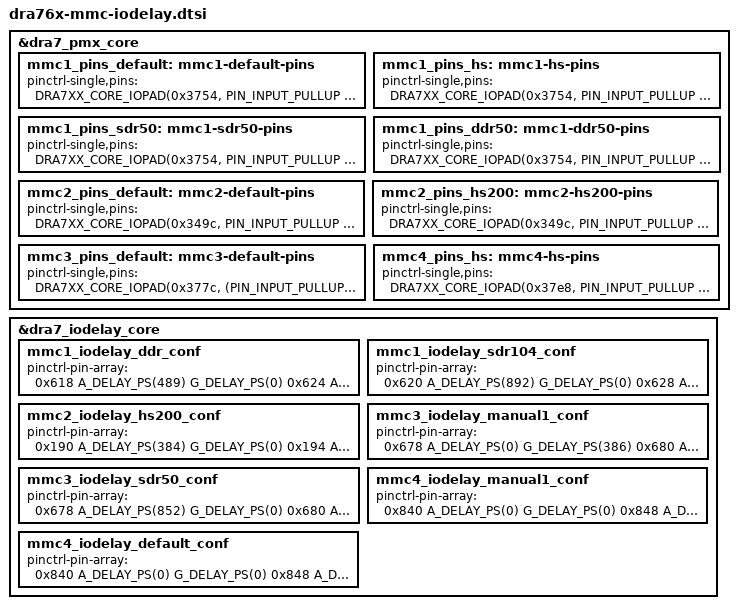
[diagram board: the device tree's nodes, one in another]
&dra7_pmx_core {
	mmc1_pins_default: mmc1-default-pins {
		pinctrl-single,pins = <
			DRA7XX_CORE_IOPAD(0x3754, PIN_INPUT_PULLUP | MUX_MODE0)  
			DRA7XX_CORE_IOPAD(0x3758, PIN_INPUT_PULLUP | MUX_MODE0)  
			DRA7XX_CORE_IOPAD(0x375c, PIN_INPUT_PULLUP | MUX_MODE0)  
			DRA7XX_CORE_IOPAD(0x3760, PIN_INPUT_PULLUP | MUX_MODE0)  
			DRA7XX_CORE_IOPAD(0x3764, PIN_INPUT_PULLUP | MUX_MODE0)  
			DRA7XX_CORE_IOPAD(0x3768, PIN_INPUT_PULLUP | MUX_MODE0)  
		>;
	};
	mmc1_pins_hs: mmc1-hs-pins {
		pinctrl-single,pins = <
			DRA7XX_CORE_IOPAD(0x3754, PIN_INPUT_PULLUP | MUX_VIRTUAL_MODE11 | MUX_MODE0)  
			DRA7XX_CORE_IOPAD(0x3758, PIN_INPUT_PULLUP | MUX_VIRTUAL_MODE11 | MUX_MODE0)  
			DRA7XX_CORE_IOPAD(0x375c, PIN_INPUT_PULLUP | MUX_VIRTUAL_MODE11 | MUX_MODE0)  
			DRA7XX_CORE_IOPAD(0x3760, PIN_INPUT_PULLUP | MUX_VIRTUAL_MODE11 | MUX_MODE0)  
			DRA7XX_CORE_IOPAD(0x3764, PIN_INPUT_PULLUP | MUX_VIRTUAL_MODE11 | MUX_MODE0)  
			DRA7XX_CORE_IOPAD(0x3768, PIN_INPUT_PULLUP | MUX_VIRTUAL_MODE11 | MUX_MODE0)  
		>;
	};
	mmc1_pins_sdr50: mmc1-sdr50-pins {
		pinctrl-single,pins = <
			DRA7XX_CORE_IOPAD(0x3754, PIN_INPUT_PULLUP | MUX_VIRTUAL_MODE10 | MUX_MODE0)	 
			DRA7XX_CORE_IOPAD(0x3758, PIN_INPUT_PULLUP | MUX_VIRTUAL_MODE10 | MUX_MODE0)	 
			DRA7XX_CORE_IOPAD(0x375c, PIN_INPUT_PULLUP | MUX_VIRTUAL_MODE10 | MUX_MODE0)	 
			DRA7XX_CORE_IOPAD(0x3760, PIN_INPUT_PULLUP | MUX_VIRTUAL_MODE10 | MUX_MODE0)	 
			DRA7XX_CORE_IOPAD(0x3764, PIN_INPUT_PULLUP | MUX_VIRTUAL_MODE10 | MUX_MODE0)	 
			DRA7XX_CORE_IOPAD(0x3768, PIN_INPUT_PULLUP | MUX_VIRTUAL_MODE10 | MUX_MODE0)	 
		>;
	};
	mmc1_pins_ddr50: mmc1-ddr50-pins {
		pinctrl-single,pins = <
			DRA7XX_CORE_IOPAD(0x3754, PIN_INPUT_PULLUP | MODE_SELECT | MUX_MODE0)	 
			DRA7XX_CORE_IOPAD(0x3758, PIN_INPUT_PULLUP | MODE_SELECT | MUX_MODE0)	 
			DRA7XX_CORE_IOPAD(0x375c, PIN_INPUT_PULLUP | MODE_SELECT | MUX_MODE0)	 
			DRA7XX_CORE_IOPAD(0x3760, PIN_INPUT_PULLUP | MODE_SELECT | MUX_MODE0)	 
			DRA7XX_CORE_IOPAD(0x3764, PIN_INPUT_PULLUP | MODE_SELECT | MUX_MODE0)	 
			DRA7XX_CORE_IOPAD(0x3768, PIN_INPUT_PULLUP | MODE_SELECT | MUX_MODE0)	 
		>;
	};
	mmc2_pins_default: mmc2-default-pins {
		pinctrl-single,pins = <
			DRA7XX_CORE_IOPAD(0x349c, PIN_INPUT_PULLUP | MUX_MODE1)  
			DRA7XX_CORE_IOPAD(0x34b0, PIN_INPUT_PULLUP | MUX_MODE1)  
			DRA7XX_CORE_IOPAD(0x34a0, PIN_INPUT_PULLUP | MUX_MODE1)  
			DRA7XX_CORE_IOPAD(0x34a4, PIN_INPUT_PULLUP | MUX_MODE1)  
			DRA7XX_CORE_IOPAD(0x34a8, PIN_INPUT_PULLUP | MUX_MODE1)  
			DRA7XX_CORE_IOPAD(0x34ac, PIN_INPUT_PULLUP | MUX_MODE1)  
			DRA7XX_CORE_IOPAD(0x348c, PIN_INPUT_PULLUP | MUX_MODE1)  
			DRA7XX_CORE_IOPAD(0x3490, PIN_INPUT_PULLUP | MUX_MODE1)  
			DRA7XX_CORE_IOPAD(0x3494, PIN_INPUT_PULLUP | MUX_MODE1)  
			DRA7XX_CORE_IOPAD(0x3498, PIN_INPUT_PULLUP | MUX_MODE1)  
		>;
	};
	mmc2_pins_hs200: mmc2-hs200-pins {
		pinctrl-single,pins = <
			DRA7XX_CORE_IOPAD(0x349c, PIN_INPUT_PULLUP | MODE_SELECT | MUX_MODE1)  
			DRA7XX_CORE_IOPAD(0x34b0, PIN_INPUT_PULLUP | MODE_SELECT | MUX_MODE1)  
			DRA7XX_CORE_IOPAD(0x34a0, PIN_INPUT_PULLUP | MODE_SELECT | MUX_MODE1)  
			DRA7XX_CORE_IOPAD(0x34a4, PIN_INPUT_PULLUP | MODE_SELECT | MUX_MODE1)  
			DRA7XX_CORE_IOPAD(0x34a8, PIN_INPUT_PULLUP | MODE_SELECT | MUX_MODE1)  
			DRA7XX_CORE_IOPAD(0x34ac, PIN_INPUT_PULLUP | MODE_SELECT | MUX_MODE1)  
			DRA7XX_CORE_IOPAD(0x348c, PIN_INPUT_PULLUP | MODE_SELECT | MUX_MODE1)  
			DRA7XX_CORE_IOPAD(0x3490, PIN_INPUT_PULLUP | MODE_SELECT | MUX_MODE1)  
			DRA7XX_CORE_IOPAD(0x3494, PIN_INPUT_PULLUP | MODE_SELECT | MUX_MODE1)  
			DRA7XX_CORE_IOPAD(0x3498, PIN_INPUT_PULLUP | MODE_SELECT | MUX_MODE1)  
		>;
	};
	mmc3_pins_default: mmc3-default-pins {
		pinctrl-single,pins = <
			DRA7XX_CORE_IOPAD(0x377c, (PIN_INPUT_PULLUP | MODE_SELECT | MUX_MODE0))  
			DRA7XX_CORE_IOPAD(0x3780, (PIN_INPUT_PULLUP | MODE_SELECT | MUX_MODE0))  
			DRA7XX_CORE_IOPAD(0x3784, (PIN_INPUT_PULLUP | MODE_SELECT | MUX_MODE0))  
			DRA7XX_CORE_IOPAD(0x3788, (PIN_INPUT_PULLUP | MODE_SELECT | MUX_MODE0))  
			DRA7XX_CORE_IOPAD(0x378c, (PIN_INPUT_PULLUP | MODE_SELECT | MUX_MODE0))  
			DRA7XX_CORE_IOPAD(0x3790, (PIN_INPUT_PULLUP | MODE_SELECT | MUX_MODE0))  
		>;
	};
	mmc4_pins_hs: mmc4-hs-pins {
		pinctrl-single,pins = <
			DRA7XX_CORE_IOPAD(0x37e8, PIN_INPUT_PULLUP | MODE_SELECT | MUX_MODE3)  
			DRA7XX_CORE_IOPAD(0x37ec, PIN_INPUT_PULLUP | MODE_SELECT | MUX_MODE3)  
			DRA7XX_CORE_IOPAD(0x37f0, PIN_INPUT_PULLUP | MODE_SELECT | MUX_MODE3)  
			DRA7XX_CORE_IOPAD(0x37f4, PIN_INPUT_PULLUP | MODE_SELECT | MUX_MODE3)  
			DRA7XX_CORE_IOPAD(0x37f8, PIN_INPUT_PULLUP | MODE_SELECT | MUX_MODE3)  
			DRA7XX_CORE_IOPAD(0x37fc, PIN_INPUT_PULLUP | MODE_SELECT | MUX_MODE3)  
		>;
	};
};
&dra7_iodelay_core {
	mmc1_iodelay_ddr_conf: mmc1_iodelay_ddr_conf {
		pinctrl-pin-array = <
			0x618 A_DELAY_PS(489) G_DELAY_PS(0)	 
			0x624 A_DELAY_PS(0) G_DELAY_PS(0)	 
			0x630 A_DELAY_PS(374) G_DELAY_PS(0)	 
			0x63c A_DELAY_PS(31) G_DELAY_PS(0)	 
			0x648 A_DELAY_PS(56) G_DELAY_PS(0)	 
			0x654 A_DELAY_PS(0) G_DELAY_PS(0)	 
			0x620 A_DELAY_PS(1355) G_DELAY_PS(0)	 
			0x628 A_DELAY_PS(0) G_DELAY_PS(0)	 
			0x62c A_DELAY_PS(0) G_DELAY_PS(0)	 
			0x634 A_DELAY_PS(0) G_DELAY_PS(0)	 
			0x638 A_DELAY_PS(0) G_DELAY_PS(4)	 
			0x640 A_DELAY_PS(0) G_DELAY_PS(0)	 
			0x644 A_DELAY_PS(0) G_DELAY_PS(0)	 
			0x64c A_DELAY_PS(0) G_DELAY_PS(0)	 
			0x650 A_DELAY_PS(0) G_DELAY_PS(0)	 
			0x658 A_DELAY_PS(0) G_DELAY_PS(0)	 
			0x65c A_DELAY_PS(0) G_DELAY_PS(0)	 
		>;
	};
	mmc1_iodelay_sdr104_conf: mmc1_iodelay_sdr104_conf {
		pinctrl-pin-array = <
			0x620 A_DELAY_PS(892) G_DELAY_PS(0)	 
			0x628 A_DELAY_PS(0) G_DELAY_PS(0)	 
			0x62c A_DELAY_PS(0) G_DELAY_PS(0)	 
			0x634 A_DELAY_PS(0) G_DELAY_PS(0)	 
			0x638 A_DELAY_PS(0) G_DELAY_PS(0)	 
			0x640 A_DELAY_PS(0) G_DELAY_PS(0)	 
			0x644 A_DELAY_PS(0) G_DELAY_PS(0)	 
			0x64c A_DELAY_PS(0) G_DELAY_PS(0)	 
			0x650 A_DELAY_PS(0) G_DELAY_PS(0)	 
			0x658 A_DELAY_PS(0) G_DELAY_PS(0)	 
			0x65c A_DELAY_PS(0) G_DELAY_PS(0)	 
		>;
	};
	mmc2_iodelay_hs200_conf: mmc2_iodelay_hs200_conf {
		pinctrl-pin-array = <
			0x190 A_DELAY_PS(384) G_DELAY_PS(0)	 
			0x194 A_DELAY_PS(350) G_DELAY_PS(174)	 
			0x1a8 A_DELAY_PS(410) G_DELAY_PS(0)	 
			0x1ac A_DELAY_PS(335) G_DELAY_PS(0)	 
			0x1b4 A_DELAY_PS(468) G_DELAY_PS(0)	 
			0x1b8 A_DELAY_PS(339) G_DELAY_PS(0)	 
			0x1c0 A_DELAY_PS(676) G_DELAY_PS(0)	 
			0x1c4 A_DELAY_PS(219) G_DELAY_PS(0)	 
			0x1d0 A_DELAY_PS(1062) G_DELAY_PS(154)	 
			0x1d8 A_DELAY_PS(640) G_DELAY_PS(0)	 
			0x1dc A_DELAY_PS(150) G_DELAY_PS(0)	 
			0x1e4 A_DELAY_PS(356) G_DELAY_PS(0)	 
			0x1e8 A_DELAY_PS(150) G_DELAY_PS(0)	 
			0x1f0 A_DELAY_PS(579) G_DELAY_PS(0)	 
			0x1f4 A_DELAY_PS(200) G_DELAY_PS(0)	 
			0x1fc A_DELAY_PS(435) G_DELAY_PS(0)	 
			0x200 A_DELAY_PS(236) G_DELAY_PS(0)	 
			0x364 A_DELAY_PS(759) G_DELAY_PS(0)	 
			0x368 A_DELAY_PS(372) G_DELAY_PS(0)	 
	      >;
	};
	mmc3_iodelay_manual1_conf: mmc3_iodelay_manual1_conf {
		pinctrl-pin-array = <
			0x678 A_DELAY_PS(0) G_DELAY_PS(386)	 
			0x680 A_DELAY_PS(605) G_DELAY_PS(0)	 
			0x684 A_DELAY_PS(0) G_DELAY_PS(0)	 
			0x688 A_DELAY_PS(0) G_DELAY_PS(0)	 
			0x68c A_DELAY_PS(0) G_DELAY_PS(0)	 
			0x690 A_DELAY_PS(171) G_DELAY_PS(0)	 
			0x694 A_DELAY_PS(0) G_DELAY_PS(0)	 
			0x698 A_DELAY_PS(0) G_DELAY_PS(0)	 
			0x69c A_DELAY_PS(221) G_DELAY_PS(0)	 
			0x6a0 A_DELAY_PS(0) G_DELAY_PS(0)	 
			0x6a4 A_DELAY_PS(0) G_DELAY_PS(0)	 
			0x6a8 A_DELAY_PS(0) G_DELAY_PS(0)	 
			0x6ac A_DELAY_PS(0) G_DELAY_PS(0)	 
			0x6b0 A_DELAY_PS(0) G_DELAY_PS(0)	 
			0x6b4 A_DELAY_PS(474) G_DELAY_PS(0)	 
			0x6b8 A_DELAY_PS(0) G_DELAY_PS(0)	 
			0x6bc A_DELAY_PS(0) G_DELAY_PS(0)	 
		>;
	};
	mmc3_iodelay_sdr50_conf: mmc3_iodelay_sdr50_conf {
		pinctrl-pin-array = <
			0x678 A_DELAY_PS(852) G_DELAY_PS(0)	 
			0x680 A_DELAY_PS(94) G_DELAY_PS(0)	 
			0x684 A_DELAY_PS(122) G_DELAY_PS(0)	 
			0x688 A_DELAY_PS(0) G_DELAY_PS(0)	 
			0x68c A_DELAY_PS(0) G_DELAY_PS(0)	 
			0x690 A_DELAY_PS(91) G_DELAY_PS(0)	 
			0x694 A_DELAY_PS(0) G_DELAY_PS(0)	 
			0x698 A_DELAY_PS(0) G_DELAY_PS(0)	 
			0x69c A_DELAY_PS(57) G_DELAY_PS(0)	 
			0x6a0 A_DELAY_PS(0) G_DELAY_PS(0)	 
			0x6a4 A_DELAY_PS(0) G_DELAY_PS(0)	 
			0x6a8 A_DELAY_PS(0) G_DELAY_PS(0)	 
			0x6ac A_DELAY_PS(0) G_DELAY_PS(0)	 
			0x6b0 A_DELAY_PS(0) G_DELAY_PS(0)	 
			0x6b4 A_DELAY_PS(375) G_DELAY_PS(0)	 
			0x6b8 A_DELAY_PS(0) G_DELAY_PS(0)	 
			0x6bc A_DELAY_PS(0) G_DELAY_PS(0)	 
		>;
	};
	mmc4_iodelay_manual1_conf: mmc4_iodelay_manual1_conf {
		pinctrl-pin-array = <
			0x840 A_DELAY_PS(0) G_DELAY_PS(0)	 
			0x848 A_DELAY_PS(1147) G_DELAY_PS(0)	 
			0x84c A_DELAY_PS(1834) G_DELAY_PS(0)	 
			0x850 A_DELAY_PS(0) G_DELAY_PS(0)	 
			0x854 A_DELAY_PS(0) G_DELAY_PS(0)	 
			0x870 A_DELAY_PS(2165) G_DELAY_PS(0)	 
			0x874 A_DELAY_PS(0) G_DELAY_PS(0)	 
			0x878 A_DELAY_PS(0) G_DELAY_PS(0)	 
			0x87c A_DELAY_PS(1929) G_DELAY_PS(64)	 
			0x880 A_DELAY_PS(0) G_DELAY_PS(0)	 
			0x884 A_DELAY_PS(0) G_DELAY_PS(0)	 
			0x888 A_DELAY_PS(1935) G_DELAY_PS(128)	 
			0x88c A_DELAY_PS(0) G_DELAY_PS(0)	 
			0x890 A_DELAY_PS(0) G_DELAY_PS(0)	 
			0x894 A_DELAY_PS(2172) G_DELAY_PS(44)	 
			0x898 A_DELAY_PS(0) G_DELAY_PS(0)	 
			0x89c A_DELAY_PS(0) G_DELAY_PS(0)	 
		>;
	};
	mmc4_iodelay_default_conf: mmc4_iodelay_default_conf {
		pinctrl-pin-array = <
			0x840 A_DELAY_PS(0) G_DELAY_PS(0)	 
			0x848 A_DELAY_PS(0) G_DELAY_PS(0)	 
			0x84c A_DELAY_PS(307) G_DELAY_PS(0)	 
			0x850 A_DELAY_PS(0) G_DELAY_PS(0)	 
			0x854 A_DELAY_PS(0) G_DELAY_PS(0)	 
			0x870 A_DELAY_PS(785) G_DELAY_PS(0)	 
			0x874 A_DELAY_PS(0) G_DELAY_PS(0)	 
			0x878 A_DELAY_PS(0) G_DELAY_PS(0)	 
			0x87c A_DELAY_PS(613) G_DELAY_PS(0)	 
			0x880 A_DELAY_PS(0) G_DELAY_PS(0)	 
			0x884 A_DELAY_PS(0) G_DELAY_PS(0)	 
			0x888 A_DELAY_PS(683) G_DELAY_PS(0)	 
			0x88c A_DELAY_PS(0) G_DELAY_PS(0)	 
			0x890 A_DELAY_PS(0) G_DELAY_PS(0)	 
			0x894 A_DELAY_PS(835) G_DELAY_PS(0)	 
			0x898 A_DELAY_PS(0) G_DELAY_PS(0)	 
			0x89c A_DELAY_PS(0) G_DELAY_PS(0)	 
		>;
	};
};
